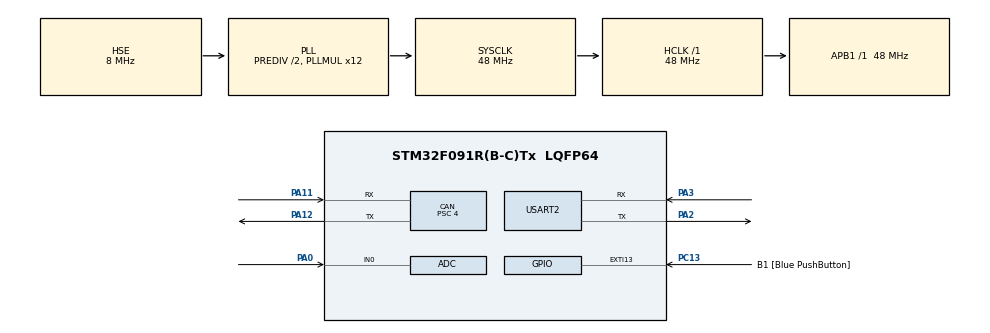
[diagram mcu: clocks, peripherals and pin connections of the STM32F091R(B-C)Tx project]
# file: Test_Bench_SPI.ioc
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ADC.ClockPrescaler=ADC_CLOCK_ASYNC_DIV1
ADC.ContinuousConvMode=ENABLE
ADC.DMAContinuousRequests=ENABLE
ADC.SamplingTime=ADC_SAMPLETIME_239CYCLES_5
CAN.AWUM=ENABLE
CAN.BS1=CAN_BS1_1TQ
CAN.CalculateBaudRate=4000000
CAN.CalculateTimeBit=250
CAN.CalculateTimeQuantum=83.33333333333333
CAN.Prescaler=4
Dma.ADC.0.Direction=DMA_PERIPH_TO_MEMORY
Dma.ADC.0.Instance=DMA1_Channel1
Dma.ADC.0.MemDataAlignment=DMA_MDATAALIGN_HALFWORD
Dma.ADC.0.MemInc=DMA_MINC_ENABLE
Dma.ADC.0.Mode=DMA_CIRCULAR
Dma.ADC.0.PeriphDataAlignment=DMA_PDATAALIGN_HALFWORD
Dma.ADC.0.PeriphInc=DMA_PINC_DISABLE
Dma.ADC.0.Priority=DMA_PRIORITY_LOW
Dma.Request0=ADC
Mcu.Family=STM32F0
Mcu.Name=STM32F091R(B-C)Tx
Mcu.Package=LQFP64
NVIC.DMA1_Ch1_IRQn=true\:0\:0\:false\:false\:true\:false\:true\:true
PA0.Mode=IN0
PA0.Signal=ADC_IN0
PA11.Mode=CAN_Activate
PA11.Signal=CAN_RX
PA12.Mode=CAN_Activate
PA12.Signal=CAN_TX
PA13.GPIO_Label=TMS
PA13.Mode=Serial_Wire
PA13.Signal=SYS_SWDIO
PA14.GPIO_Label=TCK
PA14.Mode=Serial_Wire
PA14.Signal=SYS_SWCLK
PA2.Mode=Asynchronous
PA2.Signal=USART2_TX
PA3.Mode=Asynchronous
PA3.Signal=USART2_RX
PC13.GPIO_Label=B1 [Blue PushButton]
PC13.GPIO_ModeDefaultEXTI=GPIO_MODE_IT_FALLING
PC13.Signal=GPXTI13
PC14OSC32_IN.Mode=LSE-External-Oscillator
PC14OSC32_IN.Signal=RCC_OSC32_IN
PC15OSC32_OUT.Mode=LSE-External-Oscillator
PC15OSC32_OUT.Signal=RCC_OSC32_OUT
PF0-OSC_IN.Mode=HSE-External-Clock-Source
PF0-OSC_IN.Signal=RCC_OSC_IN
PF1-OSC_OUT.Signal=RCC_OSC_OUT
ProjectManager.HeapSize=0x200
ProjectManager.StackSize=0x400
ProjectManager.TargetToolchain=STM32CubeIDE
RCC.AHBFreq_Value=48000000
RCC.APB1Freq_Value=48000000
RCC.APB1TimFreq_Value=48000000
RCC.FLatency-AdvancedSettings=FLASH_LATENCY_1
RCC.HCLKFreq_Value=48000000
RCC.PLLDivider=RCC_PREDIV_DIV2
RCC.PLLMUL=RCC_PLL_MUL12
RCC.PLLSourceVirtual=RCC_PLLSOURCE_HSE
RCC.PREFETCH_ENABLE-AdvancedSettings=1
RCC.SYSCLKFreq_VALUE=48000000
RCC.SYSCLKSource=RCC_SYSCLKSOURCE_PLLCLK
USART2.VirtualMode-Asynchronous=VM_ASYNC
board=NUCLEO-F091RC

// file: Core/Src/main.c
/* USER CODE BEGIN Header */
/* USER CODE END Header */
#include "main.h"
#include "adc.h"
#include "can.h"
#include "dma.h"
#include "usart.h"
#include "gpio.h"

/* USER CODE BEGIN Includes */
#include <stdio.h>
#include <string.h>
#include <float.h>
#include "DHAB124.h"
/* USER CODE END Includes */

/* USER CODE BEGIN PD */

#define ADC_BUF_LEN 32
uint16_t adc_buffer[ADC_BUF_LEN];
float current;

/* USER CODE END PD */

/* USER CODE BEGIN PV */
uint32_t value_adc;
float current;
/* USER CODE END PV */

void SystemClock_Config(void);

int main(void)
{

  /* MCU Configuration--------------------------------------------------------*/

  /* Reset of all peripherals, Initializes the Flash interface and the Systick. */
  HAL_Init();

  /* Configure the system clock */
  SystemClock_Config();

  /* Initialize all configured peripherals */
  MX_GPIO_Init();
  MX_DMA_Init();
  MX_ADC_Init();
  MX_USART2_UART_Init();
  MX_CAN_Init();
  /* USER CODE BEGIN 2 */

  HAL_ADCEx_Calibration_Start(&hadc);
  HAL_ADC_Start_DMA(&hadc, (uint32_t*)adc_buffer, ADC_BUF_LEN);

  /* USER CODE END 2 */

  /* Infinite loop */
  /* USER CODE BEGIN WHILE */
  while(1){
	//TODO ADC

	current = getCurrent(adc_buffer, ADC_BUF_LEN);

	//TODO SEND OVER UART2

	//HAL_UART_Transmit(&huart2, (uint8_t*)msg, strlen(msg), 100);

	HAL_Delay(10);
  }
    /* USER CODE END WHILE */

}

void SystemClock_Config(void)
{
  RCC_OscInitTypeDef RCC_OscInitStruct = {0};
  RCC_ClkInitTypeDef RCC_ClkInitStruct = {0};
  RCC_PeriphCLKInitTypeDef PeriphClkInit = {0};

  /** Initializes the RCC Oscillators according to the specified parameters
  * in the RCC_OscInitTypeDef structure.
  */
  RCC_OscInitStruct.OscillatorType = RCC_OSCILLATORTYPE_HSI14|RCC_OSCILLATORTYPE_HSE;
  RCC_OscInitStruct.HSEState = RCC_HSE_BYPASS;
  RCC_OscInitStruct.HSI14State = RCC_HSI14_ON;
  RCC_OscInitStruct.HSI14CalibrationValue = 16;
  RCC_OscInitStruct.PLL.PLLState = RCC_PLL_ON;
  RCC_OscInitStruct.PLL.PLLSource = RCC_PLLSOURCE_HSE;
  RCC_OscInitStruct.PLL.PLLMUL = RCC_PLL_MUL12;
  RCC_OscInitStruct.PLL.PREDIV = RCC_PREDIV_DIV2;
  if (HAL_RCC_OscConfig(&RCC_OscInitStruct) != HAL_OK)
  {
    Error_Handler();
  }

  /** Initializes the CPU, AHB and APB buses clocks
  */
  RCC_ClkInitStruct.ClockType = RCC_CLOCKTYPE_HCLK|RCC_CLOCKTYPE_SYSCLK
                              |RCC_CLOCKTYPE_PCLK1;
  RCC_ClkInitStruct.SYSCLKSource = RCC_SYSCLKSOURCE_PLLCLK;
  RCC_ClkInitStruct.AHBCLKDivider = RCC_SYSCLK_DIV1;
  RCC_ClkInitStruct.APB1CLKDivider = RCC_HCLK_DIV1;

  if (HAL_RCC_ClockConfig(&RCC_ClkInitStruct, FLASH_LATENCY_1) != HAL_OK)
  {
    Error_Handler();
  }
  PeriphClkInit.PeriphClockSelection = RCC_PERIPHCLK_USART2;
  PeriphClkInit.Usart2ClockSelection = RCC_USART2CLKSOURCE_PCLK1;
  if (HAL_RCCEx_PeriphCLKConfig(&PeriphClkInit) != HAL_OK)
  {
    Error_Handler();
  }
}

void Error_Handler(void)
{
}
